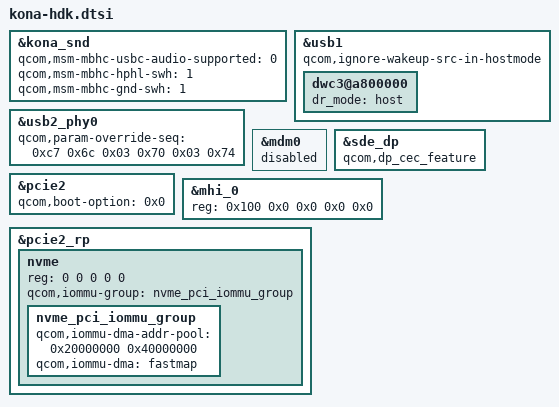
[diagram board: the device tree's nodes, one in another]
#include "kona-qrd.dtsi"

&kona_snd {
	qcom,msm-mbhc-usbc-audio-supported = <0>;
	qcom,msm-mbhc-hphl-swh = <1>;
	qcom,msm-mbhc-gnd-swh = <1>;
};

&usb1 {
	qcom,ignore-wakeup-src-in-hostmode;

	dwc3@a800000 {
		dr_mode = "host";
	};
};

&usb2_phy0 {
	qcom,param-override-seq =
		<0xc7 0x6c
		0x03 0x70
		0x03 0x74>;
};

&mdm0 {
	status = "disabled";
};

&sde_dp {
	qcom,dp_cec_feature;
};

&pcie2 {
	qcom,boot-option = <0x0>;
};

&mhi_0 {
	reg = <0x100 0x0 0x0 0x0 0x0>;
};

&pcie2_rp {
	#address-cells = <5>;
	#size-cells = <0>;

	nvme: nvme {
		reg = <0 0 0 0 0>;
		qcom,iommu-group = <&nvme_pci_iommu_group>;

		#address-cells = <1>;
		#size-cells = <1>;

		nvme_pci_iommu_group: nvme_pci_iommu_group {
			qcom,iommu-dma-addr-pool = <0x20000000 0x40000000>;
			qcom,iommu-dma = "fastmap";
		};
	};
};
